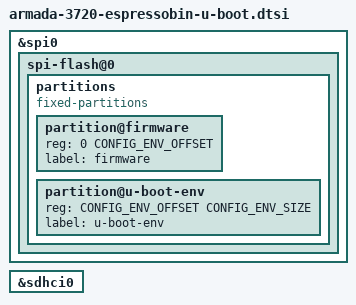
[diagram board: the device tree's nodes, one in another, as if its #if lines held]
// SPDX-License-Identifier: (GPL-2.0+ OR MIT)

#ifdef CONFIG_ENV_IS_IN_SPI_FLASH
&spi0 {
	spi-flash@0 {
		partitions {
			compatible = "fixed-partitions";
			#address-cells = <1>;
			#size-cells = <1>;

			partition@firmware {
				reg = <0 CONFIG_ENV_OFFSET>;
				label = "firmware";
			};

			partition@u-boot-env {
				reg = <CONFIG_ENV_OFFSET CONFIG_ENV_SIZE>;
				label = "u-boot-env";
			};
		};
	};
};
#endif

/*
 * U-Boot requires to have this eMMC node by default in "okay" status. U-Boot
 * at runtime changes status to "disabled" if eMMC is not present on the board.
 */
&sdhci0 {
	status = "okay";
};
